[part 1 of 2: packages /ComponentTypes/HkmcComponent/HkmcFcaAdap/DataTypes to /ComponentTypes/HkmcComponent/HkmcVehicleOutputAdap/CompuMethods]
AUTOSAR XML (schema 4-3-0)
standard types defined: boolean, boolean_CompuMethod, boolean_DataConstr, uint16, uint8, sint16
package /ComponentTypes/HkmcComponent/HkmcFcaAdap/DataTypes
  18 x impl type, all with sw-calibration-access=READ-ONLY, type-emitter=RTE:
    FcaAdap_CollisionThreatLevel_T: category=VALUE, base-type=BaseTypes/uint8, compu {0=Cx0_CollisionTL_Unknown, 1=Cx1_CollisionTL_ThreatLow, 2=Cx2_CollisionTL_ThreatMedium, 3=Cx3_CollisionTL_ThreatHigh}
    FcaAdap_DclReqVal_T: category=VALUE, base-type=BaseTypes/uint8
    FcaAdap_DecelerationRequest_T: category=VALUE, base-type=BaseTypes/uint8
    FcaAdap_FullActvReq_T: category=VALUE, base-type=BaseTypes/uint8
    FcaAdap_LongitudinalVelocity_T: category=VALUE, base-type=sint16
    FcaAdap_ObjectType_T: category=VALUE, base-type=BaseTypes/uint8, compu {0=Cx0_ObT_Unknown, 1=Cx1_ObT_Car, 2=Cx2_ObT_Motorcycle, 3=Cx3_ObT_Truck, 4=Cx4_ObT_Pedestrian, 5=Cx5_ObT_Bicycle, 6=Cx6_ObT_GeneralObject}
    FcaAdap_OnOffEquipSta_T: category=VALUE, base-type=BaseTypes/uint8, compu {0=Cx0_OnOffES_Default, 1=Cx1_OnOffES_Off, 2=Cx2_OnOffES_Warning, 3=Cx3_OnOffES_Assist, 4=Cx4_OnOffES_Reserved, 5=Cx5_OnOffES_Reserved, 6=Cx6_OnOffES_Reserved, 7=Cx7_OnOffES_Invalid, 8=Cx8_OnOffES_FCA_St_Not_Appl, 9=Cx9_OnOffES_FCA_St_Sys_Off, 16=Cx10_OnOffES_FCA_St_Sys_On, 17=Cx11_OnOffES_FCA_St_Invalid}
    FcaAdap_PrefillActvReq_T: category=VALUE, base-type=BaseTypes/uint8, compu {0=Cx0_PrefillAR_No_Pre_fill, 1=Cx1_PrefillAR_Pre_fill_act, 2=Cx2_PrefillAR_Reserved, 3=Cx3_PrefillAR_Error_Indicator}
    FcaAdap_RelVel_T: category=VALUE, base-type=BaseTypes/uint16
    FcaAdap_SnstvtyModRetVal_T: category=VALUE, base-type=BaseTypes/uint8, compu {0=Cx0_LongV_Default, 1=Cx1_LongV_Late, 2=Cx2_LongV_Normal, 3=Cx3_LongV_Early, 4=Cx4_LongV_Reserved, 5=Cx5_LongV_Reserved, 6=Cx6_LongV_Reserved, 7=Cx7_LongV_Invalid}
    FcaAdap_StbltActvReq_T: category=VALUE, base-type=BaseTypes/uint8, compu {0=Cx0_StbltAR_Release_no_alert, 1=Cx1_StbltAR_Precrash_full_retraction, 2=Cx2_StbltAR_Haptic_Warning, 3=Cx3_StbltAR_Reserved, 4=Cx4_StbltAR_Reserved, 5=Cx5_StbltAR_Reserved, 6=Cx6_StbltAR_Reserved, 7=Cx7_StbltAR_Reserved}
    FcaAdap_SysFlrSta_T:
      category=VALUE
      base-type=BaseTypes/uint8
      compu {0=Cx0_SysFlrS_Normal, 1=Cx1_SysFlrS_Temp_Unavailable_by_Camera_Fusion, 2=Cx2_SysFlrS_Temp_Unavailable_by_Radar, 3=Cx3_SysFlrS_Service_Required, 4=Cx4_SysFlrS_Temp_Unavailable_by_Camera, 5=Cx5_SysFlrS_Reserved, 6=Cx6_SysFlrS_Reserved, 7=Cx7_SysFlrS_Reserved, 8=Cx8_SysFlrS_Temp_Unavailable_by_Camera_Fusion_ADAS, 9=Cx9_SysFlrS_Temp_Unavailable_by_Radar_Fusion, 16=Cx10_SysFlrS_Reserved}
    FcaAdap_TimetoCllsn_T: category=VALUE, base-type=BaseTypes/uint8
    FcaAdap_VehStpReq_T: category=VALUE, base-type=BaseTypes/uint8, compu {0=Cx0_VehSR_No_Request, 1=Cx1_VehSR_Stop_control_is_required, 2=Cx2_VehSR_Reserved, 3=Cx3_VehSR_Error_Indicator}
    FcaAdap_WarningRequest_T: category=VALUE, base-type=BaseTypes/boolean
    FcaAdap_WrngLvlSta_T: category=VALUE, base-type=BaseTypes/uint8, compu {0=Cx0_WrngLS_No_warning, 1=Cx1_WrngLS_Warning_Level_1, 2=Cx2_WrngLS_Warning_Level_2, 3=Cx3_WrngLS_Warning_Level_3}
    FcaAdap_WrngSndSta_T: category=VALUE, base-type=BaseTypes/uint8, compu {0=Cx0_WrngSS_No_warning, 1=Cx1_WrngSS_Warning_1, 2=Cx2_WrngSS_Warning_2, 3=Cx3_WrngSS_Warning_3, 4=Cx4_WrngSS_Reserved, 5=Cx5_WrngSS_Reserved, 6=Cx6_WrngSS_Reserved, 7=Cx7_WrngSS_Error_Indicator}
    HFA_OUTPUTS_T: category=STRUCTURE
      18 x element, all with category=TYPE_REFERENCE:
        FcaAdap_WrngLvlSta: implementation-data-type=FcaAdap_WrngLvlSta_T
        FcaAdap_WrngSndSta: implementation-data-type=FcaAdap_WrngSndSta_T
        FcaAdap_PrefillActvReq: implementation-data-type=FcaAdap_PrefillActvReq_T
        FcaAdap_DclReqVal: implementation-data-type=FcaAdap_DclReqVal_T
        FcaAdap_FullActvReq: implementation-data-type=FcaAdap_FullActvReq_T
        FcaAdap_StbltActvReq: implementation-data-type=FcaAdap_StbltActvReq_T
        FcaAdap_VehStpReq: implementation-data-type=FcaAdap_VehStpReq_T
        FcaAdap_OnOffEquipSta: implementation-data-type=FcaAdap_OnOffEquipSta_T
        FcaAdap_SysFlrSta: implementation-data-type=FcaAdap_SysFlrSta_T
        FcaAdap_RelVel: implementation-data-type=FcaAdap_RelVel_T
        FcaAdap_TimetoCllsn: implementation-data-type=FcaAdap_TimetoCllsn_T
        FcaAdap_SnstvtyModRetVal: implementation-data-type=FcaAdap_SnstvtyModRetVal_T
        FcaAdap_LongitudinalVelocity: implementation-data-type=FcaAdap_LongitudinalVelocity_T
        FcaAdap_ObjectType: implementation-data-type=FcaAdap_ObjectType_T
        FcaAdap_WarningRequest: implementation-data-type=FcaAdap_WarningRequest_T
        FcaAdap_CollisionThreatLevel: implementation-data-type=FcaAdap_CollisionThreatLevel_T
        FcaAdap_DecelerationRequest: implementation-data-type=FcaAdap_DecelerationRequest_T
        FcaAdap_StandStillRequest: implementation-data-type=boolean
package /ComponentTypes/HkmcComponent/HkmcFcaAdap/PortInterfaces
  sender receiver interface IF_HFA_OUTPUTS: invalidation-policy{data-element=DE_HFA_OUTPUTS, handle-invalid=DONT-INVALIDATE}
    data DE_HFA_OUTPUTS: type=HFA_OUTPUTS_T
package /ComponentTypes/HkmcComponent/HkmcHbaAdap/DataTypes
  7 x impl type, all with sw-calibration-access=READ-ONLY, type-emitter=RTE:
    HbaAdap_errorState: category=VALUE, base-type=DataType/uint8, compu {0=Cx0_ErS_HBA_activated, 1=Cx1_ErS_HBA_faulty, 2=Cx2_ErS_HBA_temporarily_not_available}
    HbaAdap_HBA_Lamp: category=VALUE, base-type=DataType/uint8, compu {0=Cx0_Lamp_HBA_Indicator_Lamp_Off, 1=Cx1_Lamp_HBA_Indicator_Lamp_On, 2=Cx2_Lamp_Reserved, 3=Cx3_Lamp_Error_Indicator}
    HbaAdap_HBA_Opt: category=VALUE, base-type=DataType/uint8, compu {0=Cx0_Opt_None_HBA_Option, 1=Cx1_Opt_HBA_Option, 2=Cx2_Opt_Reserved, 3=Cx3_Opt_Error_Indicator}
    HbaAdap_HBA_Opt_USM: category=VALUE, base-type=DataType/uint8, compu {0=Cx0_OptU_None_HBA_Option, 1=Cx1_OptU_HBA_Function_Off, 2=Cx2_OptU_HBA_Function_On, 3=Cx3_OptU_Invalid}
    HbaAdap_highBeamStateRequest: category=VALUE, base-type=DataType/uint8, compu {0=Cx0_HighBSR_Off, 1=Cx1_HighBSR_On, 2=Cx2_HighBSR_Partial_highbeam_on}
    HbaAdap_SysState: category=VALUE, base-type=DataType/uint8, compu {0=Cx0_SysS_HBA_Disable, 1=Cx1_SysS_HBA_Enable_And_High_Beam_Off, 2=Cx2_SysS_HBA_Enable_And_High_Beam_On, 3=Cx3_SysS_Reserved, 4=Cx4_SysS_Reserved, 5=Cx5_SysS_Reserved, 6=Cx6_SysS_Reserved, 7=Cx7_SysS_System_Fail}
    HHA_OUTPUTS_T: category=STRUCTURE
      6 x element, all with category=TYPE_REFERENCE:
        HbaAdap_SysState: implementation-data-type=HbaAdap_SysState
        HbaAdap_HBA_Opt: implementation-data-type=HbaAdap_HBA_Opt
        HbaAdap_HBA_Lamp: implementation-data-type=HbaAdap_HBA_Lamp
        HbaAdap_HBA_Opt_USM: implementation-data-type=HbaAdap_HBA_Opt_USM
        HbaAdap_errorState: implementation-data-type=HbaAdap_errorState
        HbaAdap_highBeamStateRequest: implementation-data-type=HbaAdap_highBeamStateRequest
package /ComponentTypes/HkmcComponent/HkmcHbaAdap/PortInterfaces
  sender receiver interface IF_HHA_OUTPUTS: invalidation-policy{data-element=DE_HHA_OUTPUTS, handle-invalid=DONT-INVALIDATE}
    data DE_HHA_OUTPUTS: type=HHA_OUTPUTS_T
package /ComponentTypes/HkmcComponent/HkmcLkaLdwAdap/DataTypes
  39 x impl type, all with sw-calibration-access=READ-ONLY, type-emitter=RTE:
    HLLA_OUTPUTS_T: category=STRUCTURE
      38 x element, all with category=TYPE_REFERENCE:
        LkaAdap_OptUsmSta: implementation-data-type=LkaAdap_OptUsmSta
        LkaAdap_ToiFltSta: implementation-data-type=LkaAdap_ToiFltSta
        LkaAdap_ActToiSta: implementation-data-type=LkaAdap_ActToiSta
        LkaAdap_StrTrqReqVal: implementation-data-type=LkaAdap_StrTrqReqVal
        LkaAdap_RHLnWrnSta: implementation-data-type=LkaAdap_RHLnWrnSta
        LkaAdap_LHLnWrnSta: implementation-data-type=LkaAdap_LHLnWrnSta
        LkaAdap_SysWrn: implementation-data-type=LkaAdap_SysWrn
        LkaAdap_RcgSta: implementation-data-type=LkaAdap_RcgSta
        LkaAdap_HndsoffSnd: implementation-data-type=LkaAdap_HndsoffSnd
        LkaAdap_UsmMod: implementation-data-type=LkaAdap_UsmMod
        LkaAdap_SysIndReq: implementation-data-type=LkaAdap_SysIndReq
        LkaAdap_leftLaneLateral_distance: implementation-data-type=LkaAdap_leftLaneLateral_distance
        LkaAdap_rightLaneLateral_distance: implementation-data-type=LkaAdap_rightLaneLateral_distance
        LkaAdap_leftLaneheading: implementation-data-type=LkaAdap_leftLaneheading
        LkaAdap_rightLaneheading: implementation-data-type=LkaAdap_rightLaneheading
        LkaAdap_leftLanecurvature: implementation-data-type=LkaAdap_leftLanecurvature
        LkaAdap_leftLanecurvature_rate: implementation-data-type=LkaAdap_leftLanecurvature_rate
        LkaAdap_rightLanecurvature_rate: implementation-data-type=LkaAdap_rightLanecurvature_rate
        LkaAdap_leftLaneDetection_distance: implementation-data-type=LkaAdap_leftLaneDetection_distance
        LkaAdap_rightLaneDetection_distance: implementation-data-type=LkaAdap_rightLaneDetection_distance
        LkaAdap_lane_right_color: implementation-data-type=LkaAdap_lane_right_color
        LkaAdap_lane_left_color: implementation-data-type=LkaAdap_lane_left_color
        LkaAdap_leftLanemeasurement_quality: implementation-data-type=LkaAdap_leftLanemeasurement_quality
        LkaAdap_rightLanemeasurement_quality: implementation-data-type=LkaAdap_rightLanemeasurement_quality
        LkaAdap_leftLanemarkingtype: implementation-data-type=LkaAdap_leftLanemarkingtype
        LkaAdap_rightLanemarkingtype: implementation-data-type=LkaAdap_rightLanemarkingtype
        LkaAdap_neighborleftLaneLateral_distance: implementation-data-type=LkaAdap_neighborleftLaneLateral_distance
        LkaAdap_neighborrightLaneLateral_distance: implementation-data-type=LkaAdap_neighborrightLaneLateral_distance
        LkaAdap_neighborleftLaneheading: implementation-data-type=LkaAdap_neighborleftLaneheading
        LkaAdap_neighborrightLaneheading: implementation-data-type=LkaAdap_neighborrightLaneheading
        LkaAdap_neighborleftLanecurvature: implementation-data-type=LkaAdap_neighborleftLanecurvature
        LkaAdap_neighborrightLanecurvature: implementation-data-type=LkaAdap_neighborrightLanecurvature
        LkaAdap_neighborleftLanecurvature_rate: implementation-data-type=LkaAdap_neighborleftLanecurvature_rate
        LkaAdap_neighborrightLanecurvature_rate: implementation-data-type=LkaAdap_neighborrightLanecurvature_rate
        LkaAdap_neighborleftmeasurement_quality: implementation-data-type=LkaAdap_neighborleftmeasurement_quality
        LkaAdap_neighborrightmeasurement_quality: implementation-data-type=LkaAdap_neighborrightmeasurement_quality
        LkaAdap_neighborleftLanemarkingtype: implementation-data-type=LkaAdap_neighborleftLanemarkingtype
        LkaAdap_neighborrightLanemarkingtype: implementation-data-type=LkaAdap_neighborrightLanemarkingtype
    LkaAdap_ActToiSta: category=VALUE, base-type=DataType/uint8, compu {0=Cx0_ActTS_Deactivate_TOI, 1=Cx1_ActTS_Activate_TOI, 2=Cx2_ActTS_Reserved, 3=Cx3_ActTS_Error_indicator}
    LkaAdap_HndsoffSnd: category=VALUE, base-type=DataType/uint8, compu {0=Cx0_HndsoffS_Off, 1=Cx1_HndsoffS_Handsoff_Sound_Warning, 2=Cx2_HndsoffS_Reserved, 3=Cx3_HndsoffS_Reserved}
    LkaAdap_lane_left_color: category=VALUE, base-type=BaseTypes/uint8, compu {0=Cx0_LkaLaneL_Color_Unknown, 1=Cx1_LkaLaneL_Color_White, 2=Cx2_LkaLaneL_Color_YellowOrangeRed, 3=Cx3_LkaLaneL_Color_BlueGreen}
    LkaAdap_lane_right_color: category=VALUE, base-type=DataType/uint8, compu {0=Cx0_LkaLaneR_Color_Unknown, 1=Cx1_LkaLaneR_Color_White, 2=Cx2_LkaLaneR_Color_YellowOrangeRed, 3=Cx3_LkaLaneR_Color_BlueGreen}
    LkaAdap_leftLanecurvature: category=VALUE, base-type=sint16
    LkaAdap_leftLanecurvature_rate: category=VALUE, base-type=sint16
    LkaAdap_leftLaneDetection_distance: category=VALUE, base-type=BaseTypes/uint16
    LkaAdap_leftLaneheading: category=VALUE, base-type=sint16
    LkaAdap_leftLaneLateral_distance: category=VALUE, base-type=sint16
    LkaAdap_leftLanemarkingtype: category=VALUE, base-type=DataType/uint8, compu {0=Cx0_LkaMarkingTypeL_Dashed, 1=Cx1_LkaMarkingTypeL_Solid, 2=Cx2_LkaMarkingTypeL_Undecided, 3=Cx3_LkaMarkingTypeL_RoadEdge, 4=Cx4_LkaMarkingTypeL_DLMInnerSolid, 5=Cx5_LkaMarkingTypeL_DLMInnerDashed, 6=Cx6_LkaMarkingTypeL_DLMInnerUndecided, 7=Cx7_LkaMarkingTypeL_BottsDots, 8=Cx8_LkaMarkingTypeL_Barrier}
    LkaAdap_leftLanemeasurement_quality: category=VALUE, base-type=DataType/uint8, compu {0=Cx0_LkaLaneL_MQ_VeryLowQuality1, 1=Cx1_LkaLaneL_MQ_LowQuality2, 2=Cx2_LkaLaneL_MQ_Prediction, 3=Cx3_LkaLaneL_MQ_HighQuality, 7=Cx7_LkaLaneL_MQ_ErrorIndicator}
    LkaAdap_LHLnWrnSta: category=VALUE, base-type=DataType/uint8, compu {0=Cx0_LHLnWS_No_Warning, 1=Cx1_LHLnWS_HAPTIC_Warning_and_Display, 2=Cx2_LHLnWS_Acoustic_Warning_and_Display, 3=Cx3_LHLnWS_Lane_Departure_Warning, 4=Cx4_LHLnWS_Reserved, 5=Cx5_LHLnWS_Reserved}
    LkaAdap_neighborleftLanecurvature: category=VALUE, base-type=sint16
    LkaAdap_neighborleftLanecurvature_rate: category=VALUE, base-type=sint16
    LkaAdap_neighborleftLaneheading: category=VALUE, base-type=sint16
    LkaAdap_neighborleftLaneLateral_distance: category=VALUE, base-type=sint16
    LkaAdap_neighborleftLanemarkingtype: category=VALUE, base-type=DataType/uint8, compu {0=Cx0_LkaNMarkingTypeL_Dashed, 1=Cx1_LkaNMarkingTypeL_Solid, 2=Cx2_LkaNMarkingTypeL_Undecided, 3=Cx3_LkaNMarkingTypeL_RoadEdge, 4=Cx4_LkaNMarkingTypeL_DLMInnerSolid, 5=Cx5_LkaNMarkingTypeL_DLMInnerDashed, 6=Cx6_LkaNMarkingTypeL_DLMInnerUndecided, 7=Cx7_LkaNMarkingTypeL_BottsDots, 8=Cx8_LkaNMarkingTypeL_Barrier}
    LkaAdap_neighborleftmeasurement_quality: category=VALUE, base-type=DataType/uint8, compu {0=Cx0_LkaLaneL_MQ_VeryLowQuality1, 1=Cx1_LkaLaneL_MQ_LowQuality2, 2=Cx2_LkaLaneL_MQ_Prediction, 3=Cx3_LkaLaneL_MQ_HighQuality, 7=Cx7_LkaLaneL_MQ_ErrorIndicator}
    LkaAdap_neighborrightLanecurvature: category=VALUE, base-type=sint16
    LkaAdap_neighborrightLanecurvature_rate: category=VALUE, base-type=sint16
    LkaAdap_neighborrightLaneheading: category=VALUE, base-type=sint16
    LkaAdap_neighborrightLaneLateral_distance: category=VALUE, base-type=sint16
    LkaAdap_neighborrightLanemarkingtype: category=VALUE, base-type=DataType/uint8, compu {0=Cx0_LkaNMarkingTypeR_Dashed, 1=Cx1_LkaNMarkingTypeR_Solid, 2=Cx2_LkaNMarkingTypeR_Undecided, 3=Cx3_LkaNMarkingTypeR_RoadEdge, 4=Cx4_LkaNMarkingTypeR_DLMInnerSolid, 5=Cx5_LkaNMarkingTypeR_DLMInnerDashed, 6=Cx6_LkaNMarkingTypeR_DLMInnerUndecided, 7=Cx7_LkaNMarkingTypeR_BottsDots, 8=Cx8_LkaNMarkingTypeR_Barrier}
    LkaAdap_neighborrightmeasurement_quality: category=VALUE, base-type=DataType/uint8, compu {0=Cx0_LkaLaneR_MQ_VeryLowQuality1, 1=Cx1_LkaLaneR_MQ_LowQuality2, 2=Cx2_LkaLaneR_MQ_Prediction, 3=Cx3_LkaLaneR_MQ_HighQuality, 7=Cx7_LkaLaneR_MQ_ErrorIndicator}
    LkaAdap_OptUsmSta: category=VALUE, base-type=DataType/uint8, compu {0=Cx0_OptUS_None_LKA_LDW_Option_Default, 1=Cx1_OptUS_LDW, 2=Cx2_OptUS_LKA, 3=Cx3_OptUS_ACTIVE_LKA, 4=Cx4_OptUS_LDW_Only, 5=Cx5_OptUS_LDW_only_OFF, 6=Cx6_OptUS_LDW_LKA_OFF, 7=Cx7_OptUS_Invalid, 8=Cx8_OptUS_Reserved}
    LkaAdap_RcgSta: category=VALUE, base-type=DataType/uint8, compu {0=Cx0_RcgS_Not_Recognized, 1=Cx1_RcgS_Left_Lane_Recognized, 2=Cx2_RcgS_Right_Lane_Recognized, 3=Cx3_RcgS_Full_Lane_Recognized, 4=Cx4_RcgS_Reserved, 5=Cx5_RcgS_Reserved, 6=Cx6_RcgS_Reserved, 7=Cx7_RcgS_Reserved}
    LkaAdap_RHLnWrnSta: category=VALUE, base-type=DataType/uint8, compu {0=Cx0_RHLnWS_No_Warning, 1=Cx1_RHLnWS_HAPTIC_Warning_and_Display, 2=Cx2_RHLnWS_Acoustic_Warning_and_Display, 3=Cx3_RHLnWS_Lane_Departure_Warning, 4=Cx4_RHLnWS_Reserved, 5=Cx5_RHLnWS_Reserved}
    LkaAdap_rightLanecurvature_rate: category=VALUE, base-type=sint16
    LkaAdap_rightLaneDetection_distance: category=VALUE, base-type=BaseTypes/uint16
    LkaAdap_rightLaneheading: category=VALUE, base-type=sint16
    LkaAdap_rightLaneLateral_distance: category=VALUE, base-type=sint16
    LkaAdap_rightLanemarkingtype: category=VALUE, base-type=DataType/uint8, compu {0=Cx0_LkaMarkingTypeR_Dashed, 1=Cx1_LkaMarkingTypeR_Solid, 2=Cx2_LkaMarkingTypeR_Undecided, 3=Cx3_LkaMarkingTypeR_RoadEdge, 4=Cx4_LkaMarkingTypeR_DLMInnerSolid, 5=Cx5_LkaMarkingTypeR_DLMInnerDashed, 6=Cx6_LkaMarkingTypeR_DLMInnerUndecided, 7=Cx7_LkaMarkingTypeR_BottsDots, 8=Cx8_LkaMarkingTypeR_Barrier}
    LkaAdap_rightLanemeasurement_quality: category=VALUE, base-type=DataType/uint8, compu {0=Cx0_LkaLaneR_MQ_VeryLowQuality1, 1=Cx1_LkaLaneR_MQ_LowQuality2, 2=Cx2_LkaLaneR_MQ_Prediction, 3=Cx3_LkaLaneR_MQ_HighQuality, 7=Cx7_LkaLaneR_MQ_ErrorIndicator}
    LkaAdap_StrTrqReqVal: category=VALUE, base-type=DataType/uint8, compu {0=In_analysis}
    LkaAdap_SysIndReq: category=VALUE, base-type=DataType/uint8, compu {0=Cx0_SysIR_Off, 1=Cx1_SysIR_White_On, 2=Cx2_SysIR_Lane_Recognized_Green_On, 3=Cx3_SysIR_Lane_Departure_Green_Blink, 4=Cx4_SysIR_System_Fail_Orange_On, 5=Cx5_SysIR_Not_Calibrated_Orange_Blink, 6=Cx6_SysIR_Regulation_Orange_On, 7=Cx7_SysIR_White_Blink, 8=Cx8_SysIR_Unavailable_Gray_On, 9=Cx9_SysIR_Reserved}
    LkaAdap_SysWrn:
      category=VALUE
      base-type=DataType/uint8
      compu {0=Cx0_SysW_No_Info, 1=Cx1_SysW_Reserved, 2=Cx2_SysW_Reserved, 3=Cx3_SysW_Reserved, 4=Cx4_SysW_HandsOff_Warning_1, 5=Cx5_SysW_HandsOff_Warning_2, 6=Cx6_SysW_HandsOff_Warning_3, 7=Cx7_SysW_Reserved, 8=Cx8_SysW_Reserved, 9=Cx9_SysW_System_Automatic_off, 10=CxA_SysW_Reserved, 11=CxB_SysW_Reserved, 12=CxC_SysW_Reserved, 13=CxD_SysW_Reserved, 14=CxE_SysW_Reserved, 15=CxF_SysW_System_Fail}
    LkaAdap_ToiFltSta: category=VALUE, base-type=DataType/uint8, compu {0=Cx0_ToiFS_No_Fault, 1=Cx1_ToiFS_Fault_Present, 2=Cx2_ToiFS_Reserved, 3=Cx3_ToiFS_Error_indicatorr}
    LkaAdap_UsmMod: category=VALUE, base-type=DataType/uint8, compu {0=Cx0_UsmM_NONE, 1=Cx1_UsmM_LKA_1_Mode, 2=Cx2_UsmM_LKA_2_Mode, 3=Cx3_UsmM_LDW, 4=Cx4_Reserved}
package /ComponentTypes/HkmcComponent/HkmcLkaLdwAdap/PortInterfaces
  sender receiver interface IF_HLLA_OUTPUTS: invalidation-policy{data-element=DE_HLLA_OUTPUTS, handle-invalid=DONT-INVALIDATE}
    data DE_HLLA_OUTPUTS: type=HLLA_OUTPUTS_T
package /ComponentTypes/HkmcComponent/HkmcVehicleOutputAdap
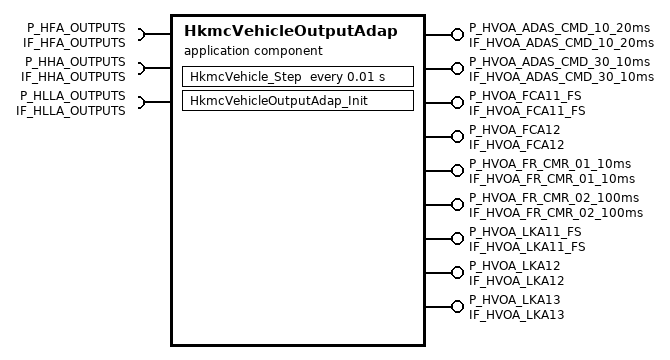
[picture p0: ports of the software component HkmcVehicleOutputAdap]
  application sw component type HkmcVehicleOutputAdap
    9 x provide port:
      P_HVOA_ADAS_CMD_10_20ms: nonqueued-sender-com-spec{data-element=DE_HVOA_ADAS_CMD_10_20ms, init-value=fields=[ADAS_CMD_AlvCnt10Val:0, ADAS_CMD_Crc10Val:65535, FCA_DclReqVal:0, FCA_FullActvReq:0, FCA_HydrlcBstAsstReq:0, FCA_OnOffEquipSta:0, FCA_PartialActvReq:0, FCA_PrefillActvReq:0, FCA_RelVel:0, FCA_SnstvtyModRetVal:0, FCA_StbltActvReq:0, FCA_SysFlrSta:0, FCA_TimetoCllsn:254, FCA_VehStpReq:0, FCA_WrngLvlSta:0, FCA_WrngSndSta:0, FCA_WrngTrgtDis:0]}, provided-interface=IF_HVOA_ADAS_CMD_10_20ms
      P_HVOA_ADAS_CMD_30_10ms: nonqueued-sender-com-spec{data-element=DE_HVOA_ADAS_CMD_30_10ms, init-value=fields=[ADAS_ActToiSta:0, ADAS_CMD_AlvCnt30Val:0, ADAS_CMD_Crc30Val:65535, ADAS_Damping_Gain:100, ADAS_StrTqReqVal:1024, ADAS_ToiFltSta:0, Info_PedtrnDst:0, LKA_HndsoffSnd:0, LKA_LHLnWrnSta:0, LKA_OptUsmSta:0, LKA_RcgSta:0, LKA_RHLnWrnSta:0, LKA_StrSnd:0, LKA_SysIndReq:0, LKA_SysWrn:0, LKA_UsmMod:0]}, provided-interface=IF_HVOA_ADAS_CMD_30_10ms
      P_HVOA_FCA11_FS: nonqueued-sender-com-spec{data-element=DE_HVOA_FCA11_FS, init-value=fields=[CF_VSM_BeltCmd:0, CF_VSM_DecCmdAct:0, CF_VSM_HBACmd:0, CF_VSM_Prefill:0, CF_VSM_Warn:0, CR_FCA_Alive:0, CR_VSM_DecCmd:0, FCA_CmdAct:0, FCA_CRC:255, FCA_DrvSetStatus:1, FCA_Failinfo:0, FCA_RelativeVelocity:0, FCA_Sensor_Type:0, FCA_Status:0, FCA_StopReq:0, FCA_TimetoCollision:0, FCA_WrngSndSta:0]}, provided-interface=IF_HVOA_FCA11_FS
      P_HVOA_FCA12: nonqueued-sender-com-spec{data-element=DE_HVOA_FCA12, init-value=fields=[FCA_DrvSetState:2, FCA_USM:3, FCA_WarningTargetDisplay:0]}, provided-interface=IF_HVOA_FCA12
      P_HVOA_FR_CMR_01_10ms: nonqueued-sender-com-spec{data-element=DE_HVOA_FR_CMR_01_10ms, init-value=fields=[DAW_LVDA_OptUsmSta:0, DAW_LVDA_PUDis:0, DAW_OptUsmSta:0, DAW_SnstvtyModRetVal:0, DAW_SysSta:0, DAW_TimeRstReq:0, DAW_WrnMsgSta:0, FCA_Equip_MFC:0, FR_CMR_AlvCnt1Val:0, FR_CMR_Crc1Val:65535, FR_CMR_ReqADASMapMsgVal:0, FR_CMR_SCCEquipSta:0, FR_CMR_SwVer1Val:0, FR_CMR_SwVer2Val:0, HBA_IndLmpReq:0, HBA_OptUsmSta:0, HBA_SysOptSta:0, HBA_SysSta:0]}, provided-interface=IF_HVOA_FR_CMR_01_10ms
      P_HVOA_FR_CMR_02_100ms: nonqueued-sender-com-spec{data-element=DE_HVOA_FR_CMR_02_100ms, init-value=fields=[FR_CMR_AlvCnt2Val:0, FR_CMR_Crc2Val:0, ISLA_AddtnlSign:0, ISLA_AutoUsmSta:0, ISLA_Cntry:15, ISLA_IcyWrn:0, ISLA_OffstUsmSta:0, ISLA_OptUsmSta:0, ISLA_Popup:0, ISLA_SchoolZone:0, ISLA_SpdChgReq:0, ISLA_SpdwOffst:0, ISLA_SpdWrn:0, ISLA_SwIgnoreReq:0, ISLA_SymFlashMod:0, ISLW_NoPassingInfoDis:0, ISLW_OptUsmSta:0, ISLW_OvrlpSignDis:0, ISLW_SpdCluDisSubCond1:0, ISLW_SpdCluDisSubCond2:0, ISLW_SpdCluMainDis:0, ISLW_SpdCluSubMainDis:0, ISLW_SpdNaviDisSubCond1:0, ISLW_SpdNaviDisSubCond2:0, ISLW_SpdNaviMainDis:0, ISLW_SpdNaviSubMainDis:0, ISLW_SubCondinfoSta1:0, ISLW_SubCondinfoSta2:0, ISLW_SysSta:0]}, provided-interface=IF_HVOA_FR_CMR_02_100ms
      P_HVOA_LKA11_FS: nonqueued-sender-com-spec{data-element=DE_HVOA_LKA11_FS, init-value=fields=[CF_HBA_Lamp:0, CF_HBA_Opt:0, CF_HBA_Opt_USM:0, CF_HBA_SysState:0, CF_LKA_ActToi:0, CF_LKA_CRC:255, CF_LKA_FusionState:0, CF_LKA_HandsOff_Snd:0, CF_LKA_LaneRecogState:0, CF_LKA_LHWarning:0, CF_LKA_MsgCount:0, CF_LKA_Opt_USM:0, CF_LKA_RHWarning:0, CF_LKA_SymbolState:0, CF_LKA_SysState:0, CF_LKA_SysWarning:0, CF_LKA_ToiFlt:0, CF_LKA_USM_Mode:0, CR_LKA_StrToqReq:1024]}, provided-interface=IF_HVOA_LKA11_FS
      P_HVOA_LKA12: nonqueued-sender-com-spec{data-element=DE_HVOA_LKA12, init-value=fields=[CF_DAW_Opt_USM_NEW:0, CF_DAW_Status:0, CF_DAW_TimeReset:0, CF_DAW_Warn:0, CF_ISLW_Addinfo_Display:0, CF_ISLW_OvrlapSign_Dis:0, CF_ISLW_Spd_Dis_CLU_Main:0, CF_ISLW_Spd_Dis_NAVI_Main:0, CF_ISLW_Status:0, CF_LeadVehDptAlert_Display:0, CF_LeadVehDptAlert_USM:0, ISLA_IcyWrn:0, ISLA_SpdChgReq:0, ISLA_SpdwOffst:0, ISLA_SpdWrn:0, ISLA_SwIgnoreReq:0, ISLA_SymFlashMod:0]}, provided-interface=IF_HVOA_LKA12
      P_HVOA_LKA13: nonqueued-sender-com-spec{data-element=DE_HVOA_LKA13, init-value=fields=[CF_ISLW_ConInfo_Sta_Con1:0, CF_ISLW_ConInfo_Sta_Con2:0, CF_ISLW_Spd_Dis_CLU_Con1:0, CF_ISLW_Spd_Dis_CLU_Con2:0, CF_ISLW_Spd_Dis_NAVI_Con1:0, CF_ISLW_Spd_Dis_NAVI_Con2:0, ISLA_AddtnlSign:0, ISLA_AutoUsmSta:0, ISLA_Cntry:15, ISLA_OffstUsmSta:0, ISLA_OptUsmSta:0, ISLA_Popup:0, ISLA_SchoolZone:0]}, provided-interface=IF_HVOA_LKA13
    require port P_HFA_OUTPUTS: nonqueued-receiver-com-spec{data-element=DE_HFA_OUTPUTS, filter=data-filter-type=ALWAYS, init-value=fields=[FcaAdap_WrngLvlSta:0, FcaAdap_WrngSndSta:0, FcaAdap_PrefillActvReq:0, FcaAdap_DclReqVal:0, FcaAdap_FullActvReq:0, FcaAdap_StbltActvReq:0, FcaAdap_VehStpReq:0, FcaAdap_OnOffEquipSta:0, FcaAdap_SysFlrSta:0, FcaAdap_RelVel:0, FcaAdap_TimetoCllsn:0, FcaAdap_SnstvtyModRetVal:0, FcaAdap_LongitudinalVelocity:0, FcaAdap_ObjectType:0, FcaAdap_WarningRequest:0, FcaAdap_CollisionThreatLevel:0, FcaAdap_DecelerationRequest:0, FcaAdap_StandStillRequest:0]}, required-interface=IF_HFA_OUTPUTS
    require port P_HHA_OUTPUTS: nonqueued-receiver-com-spec{data-element=DE_HHA_OUTPUTS, filter=data-filter-type=ALWAYS}, required-interface=IF_HHA_OUTPUTS
    require port P_HLLA_OUTPUTS: nonqueued-receiver-com-spec{data-element=DE_HLLA_OUTPUTS, filter=data-filter-type=ALWAYS}, required-interface=IF_HLLA_OUTPUTS
    behavior HkmcVehicleOutputAdap_InternalBehavior
      timing event HkmcVehicle_Step_TE: start-on-event=HkmcVehicle_Step, period=0.01
      init event HkmcVehicleOutputAdap_InitEvent: start-on-event=HkmcVehicleOutputAdap_Init
      runnable HkmcVehicle_Step
        data-receive-point-by-arguments:
          access REC_P_HFA_OUTPUTS_DE_HFA_OUTPUTS: accessed-variable=P_HFA_OUTPUTS.DE_HFA_OUTPUTS
          access REC_P_HHA_OUTPUTS_DE_HHA_OUTPUTS: accessed-variable=P_HHA_OUTPUTS.DE_HHA_OUTPUTS
          access REC_P_HLLA_OUTPUTS_DE_HLLA_OUTPUTS: accessed-variable=P_HLLA_OUTPUTS.DE_HLLA_OUTPUTS
        data-send-points:
          9 x access:
            SEND_P_HVOA_ADAS_CMD_10_20ms_DE_HVOA_ADAS_CMD_10_20ms: accessed-variable=P_HVOA_ADAS_CMD_10_20ms.DE_HVOA_ADAS_CMD_10_20ms
            SEND_P_HVOA_ADAS_CMD_30_10ms_DE_HVOA_ADAS_CMD_30_10ms: accessed-variable=P_HVOA_ADAS_CMD_30_10ms.DE_HVOA_ADAS_CMD_30_10ms
            SEND_P_HVOA_FCA11_FS_DE_HVOA_FCA11_FS: accessed-variable=P_HVOA_FCA11_FS.DE_HVOA_FCA11_FS
            SEND_P_HVOA_FCA12_DE_HVOA_FCA12: accessed-variable=P_HVOA_FCA12.DE_HVOA_FCA12
            SEND_P_HVOA_FR_CMR_01_10ms_DE_HVOA_FR_CMR_01_10ms: accessed-variable=P_HVOA_FR_CMR_01_10ms.DE_HVOA_FR_CMR_01_10ms
            SEND_P_HVOA_FR_CMR_02_100ms_DE_HVOA_FR_CMR_02_100ms: accessed-variable=P_HVOA_FR_CMR_02_100ms.DE_HVOA_FR_CMR_02_100ms
            SEND_P_HVOA_LKA11_FS_DE_HVOA_LKA11_FS: accessed-variable=P_HVOA_LKA11_FS.DE_HVOA_LKA11_FS
            SEND_P_HVOA_LKA12_DE_HVOA_LKA12: accessed-variable=P_HVOA_LKA12.DE_HVOA_LKA12
            SEND_P_HVOA_LKA13_DE_HVOA_LKA13: accessed-variable=P_HVOA_LKA13.DE_HVOA_LKA13
      runnable HkmcVehicleOutputAdap_Init
        data-receive-point-by-arguments:
          access REC_P_HFA_OUTPUTS_DE_HFA_OUTPUTS: accessed-variable=P_HFA_OUTPUTS.DE_HFA_OUTPUTS
          access REC_P_HHA_OUTPUTS_DE_HHA_OUTPUTS: accessed-variable=P_HHA_OUTPUTS.DE_HHA_OUTPUTS
          access REC_P_HLLA_OUTPUTS_DE_HLLA_OUTPUTS: accessed-variable=P_HLLA_OUTPUTS.DE_HLLA_OUTPUTS
        data-send-points:
          9 x access:
            SEND_P_HVOA_ADAS_CMD_10_20ms_DE_HVOA_ADAS_CMD_10_20ms: accessed-variable=P_HVOA_ADAS_CMD_10_20ms.DE_HVOA_ADAS_CMD_10_20ms
            SEND_P_HVOA_ADAS_CMD_30_10ms_DE_HVOA_ADAS_CMD_30_10ms: accessed-variable=P_HVOA_ADAS_CMD_30_10ms.DE_HVOA_ADAS_CMD_30_10ms
            SEND_P_HVOA_FCA11_FS_DE_HVOA_FCA11_FS: accessed-variable=P_HVOA_FCA11_FS.DE_HVOA_FCA11_FS
            SEND_P_HVOA_FCA12_DE_HVOA_FCA12: accessed-variable=P_HVOA_FCA12.DE_HVOA_FCA12
            SEND_P_HVOA_FR_CMR_01_10ms_DE_HVOA_FR_CMR_01_10ms: accessed-variable=P_HVOA_FR_CMR_01_10ms.DE_HVOA_FR_CMR_01_10ms
            SEND_P_HVOA_FR_CMR_02_100ms_DE_HVOA_FR_CMR_02_100ms: accessed-variable=P_HVOA_FR_CMR_02_100ms.DE_HVOA_FR_CMR_02_100ms
            SEND_P_HVOA_LKA11_FS_DE_HVOA_LKA11_FS: accessed-variable=P_HVOA_LKA11_FS.DE_HVOA_LKA11_FS
            SEND_P_HVOA_LKA12_DE_HVOA_LKA12: accessed-variable=P_HVOA_LKA12.DE_HVOA_LKA12
            SEND_P_HVOA_LKA13_DE_HVOA_LKA13: accessed-variable=P_HVOA_LKA13.DE_HVOA_LKA13
  swc implementation HkmcVehicleOutputAdap_Implementation: behavior=HkmcVehicleOutputAdap_InternalBehavior
    code-descriptors:
      code Default: artifact-descriptors=autosar-engineering-object={short-label=Default, category=SWSRC}
package /ComponentTypes/HkmcComponent/HkmcVehicleOutputAdap/CompuMethods
  compu method CM_FCA_DrvSetState: 0=Cx0_DrvSS_Default, 1=Cx1_DrvSS_Late, 2=Cx2_DrvSS_Normal, 3=Cx3_DrvSS_Early, 4=Cx4_DrvSS_Reserved, 5=Cx5_DrvSS_Reserved, 6=Cx6_DrvSS_Reserved, 7=Cx7_DrvSS_Invalid
